# STM32G491 register map
File version: 2.8
CPU: CM4 r0p1, little endian, MPU, FPU, 4 interrupt priority bits
Registers are 32-bit, read-write, reset 0x0 unless marked. A register's access mark holds for its fields unless they carry their own. Offsets are from the block's base; [hi:lo] are bit positions.

## CORDIC — CORDIC Co-processor
Base 0x40020C00
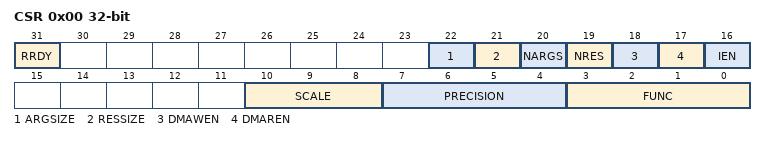
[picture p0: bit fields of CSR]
0x00 CSR — CORDIC Control Status register
  [31] RRDY
    on read: 0=NotReady (Results from computation are not read); 1=Ready (Results are ready, this flag will be automatically cleared once value is read)
  [22] ARGSIZE
    0=Bits32 (Use 32 bit input values); 1=Bits16 (Use 16 bit input values)
  [21] RESSIZE
    0=Bits32 (Use 32 bit output values); 1=Bits16 (Use 16 bit output values)
  [20] NARGS
    0=Num1 (Only single argument write is needed for next calculation); 1=Num2 (Two argument writes need to be performed for next calculation)
  [19] NRES
    0=Num1 (Only single result value will be returned. After a single read RRDY will be automatically cleared); 1=Num2 (Two return reads need to be performed. After two reads RRDY will be automatically cleared)
  [18] DMAWEN
    0=Disabled (No DMA channel writes are generated); 1=Enabled (Write requests are generated on the DMA channel when no operation is pending)
  [17] DMAREN
    0=Disabled (No DMA channel reads are generated); 1=Enabled (Read requests are generated on the DMA channel when RRDY flag is set)
  [16] IEN
    0=Disabled (Disable interrupt request generation); 1=Enabled (Enable interrupt request generation)
  [10:8] SCALE — Scaling factor (2^-n for arguments, 2^n for results)
  [7:4] PRECISION — Precision (number of iterations/cycles) required
    1=Iters4 (4 iterations); 2=Iters8 (8 iterations); 3=Iters12 (12 iterations); 4=Iters16 (16 iterations); 5=Iters20 (20 iterations); 6=Iters24 (24 iterations); 7=Iters28 (28 iterations); 8=Iters32 (32 iterations); 9=Iters36 (36 iterations); 10=Iters40 (40 iterations); 11=Iters44 (44 iterations); 12=Iters48 (48 iterations); 13=Iters52 (52 iterations); 14=Iters56 (56 iterations); 15=Iters60 (60 iterations)
  [3:0] FUNC
    0=Cosine function; 1=Sine function; 2=Phase function; 3=Modulus function; 4=Arctangent function; 5=Hyperbolic Cosine function; 6=Hyperbolic Sine function; 7=Arctanh function; 8=Natural Logarithm function; 9=Square Root function
0x04 WDATA — CORDIC argument register
  [31:0] ARG
0x08 RDATA ro — CORDIC result register
  [31:0] RES

## CRC — Cyclic redundancy check calculation unit
Base 0x40023000
0x00 DR reset 0xFFFFFFFF — Data register
  [31:0] DR — Data register bits
0x00 DR8 8-bit reset 0xFF (alternate view of DR) — Data register - byte sized
  [7:0] DR8 — Data register bits
0x00 DR16 16-bit reset 0xFFFF (alternate view of DR) — Data register - half-word sized
  [15:0] DR16 — Data register bits
0x04 IDR — Independent data register
  [31:0] IDR — General-purpose 8-bit data register bits
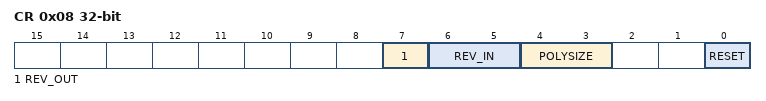
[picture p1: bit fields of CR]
0x08 CR access per field — Control register
  [7] REV_OUT rw — Reverse output data
    0=Normal (Bit order not affected); 1=Reversed (Bit reversed output)
  [6:5] REV_IN rw — Reverse input data
    0=Normal (Bit order not affected); 1=Byte (Bit reversal done by byte); 2=HalfWord (Bit reversal done by half-word); 3=Word (Bit reversal done by word)
  [4:3] POLYSIZE rw — Polynomial size
    0=32-bit polynomial; 1=16-bit polynomial; 2=8-bit polynomial; 3=7-bit polynomial
  [0] RESET wo — RESET bit
    1=Resets the CRC calculation unit and sets the data register to 0xFFFF FFFF
0x10 INIT reset 0xFFFFFFFF — Initial CRC value
  [31:0] INIT — Programmable initial CRC value
0x14 POL reset 0x4C11DB7 — polynomial
  [31:0] POL — Programmable polynomial

## DBGMCU — Debug support
Base 0xE0042000
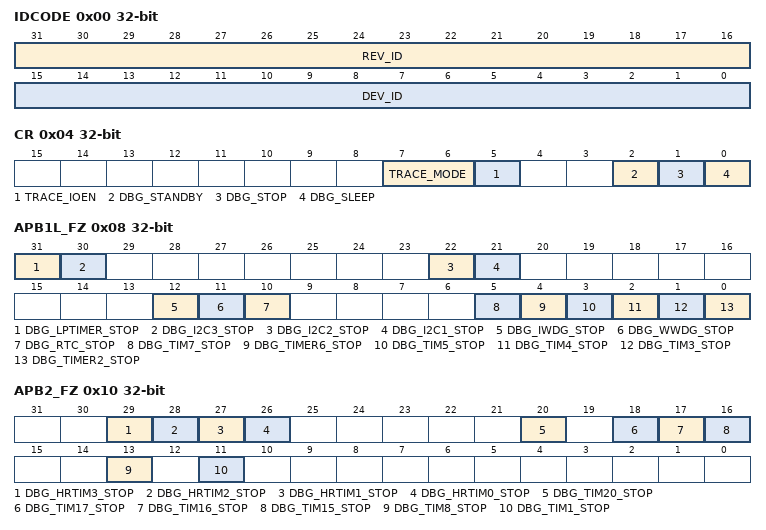
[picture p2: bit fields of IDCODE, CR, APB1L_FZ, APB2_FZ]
0x00 IDCODE ro — MCU Device ID Code Register
  [31:16] REV_ID — Revision Identifier
  [15:0] DEV_ID — Device Identifier
0x04 CR — Debug MCU Configuration Register
  [7:6] TRACE_MODE — Trace pin assignment control
  [5] TRACE_IOEN — Trace pin assignment control
  [2] DBG_STANDBY — Debug Standby Mode
  [1] DBG_STOP — Debug Stop Mode
  [0] DBG_SLEEP — Debug Sleep Mode
0x08 APB1L_FZ — APB Low Freeze Register 1
  [31] DBG_LPTIMER_STOP — LPTIM1 counter stopped when core is halted
  [30] DBG_I2C3_STOP — I2C3 SMBUS timeout mode stopped when core is halted
  [22] DBG_I2C2_STOP — I2C2 SMBUS timeout mode stopped when core is halted
  [21] DBG_I2C1_STOP — I2C1 SMBUS timeout mode stopped when core is halted
  [12] DBG_IWDG_STOP — Debug Independent Wachdog stopped when Core is halted
  [11] DBG_WWDG_STOP — Debug Window Wachdog stopped when Core is halted
  [10] DBG_RTC_STOP — Debug RTC stopped when Core is halted
  [5] DBG_TIM7_STOP — TIM7 counter stopped when core is halted
  [4] DBG_TIMER6_STOP — Debug Timer 6 stopped when Core is halted
  [3] DBG_TIM5_STOP — TIM5 counter stopped when core is halted
  [2] DBG_TIM4_STOP — TIM4 counter stopped when core is halted
  [1] DBG_TIM3_STOP — TIM3 counter stopped when core is halted
  [0] DBG_TIMER2_STOP — Debug Timer 2 stopped when Core is halted
0x0C APB1H_FZ — APB Low Freeze Register 2
  [1] DBG_I2C4_STOP
0x10 APB2_FZ — APB High Freeze Register
  [29] DBG_HRTIM3_STOP — DBG_HRTIM0_STOP
  [28] DBG_HRTIM2_STOP — DBG_HRTIM0_STOP
  [27] DBG_HRTIM1_STOP — DBG_HRTIM0_STOP
  [26] DBG_HRTIM0_STOP
  [20] DBG_TIM20_STOP — TIM20counter stopped when core is halted
  [18] DBG_TIM17_STOP — TIM17 counter stopped when core is halted
  [17] DBG_TIM16_STOP — TIM16 counter stopped when core is halted
  [16] DBG_TIM15_STOP — TIM15 counter stopped when core is halted
  [13] DBG_TIM8_STOP — TIM8 counter stopped when core is halted
  [11] DBG_TIM1_STOP — TIM1 counter stopped when core is halted
